# PM_RT register map
Vendor: Texas Instruments
Peripheral module from a debugger description file (folder omap34xx).
Registers are 64-bit, access per field, reset 0x0 unless marked. A register's access mark holds for its fields unless they carry their own. Offsets are as the file gives them; lines under a group give offsets from that group; [hi:lo] are bit positions; {n}, {i} and the like mark numbered series; 'fields as' and 'values as' point back to an identical list; <NAME> marks a mode.

## PM_RT
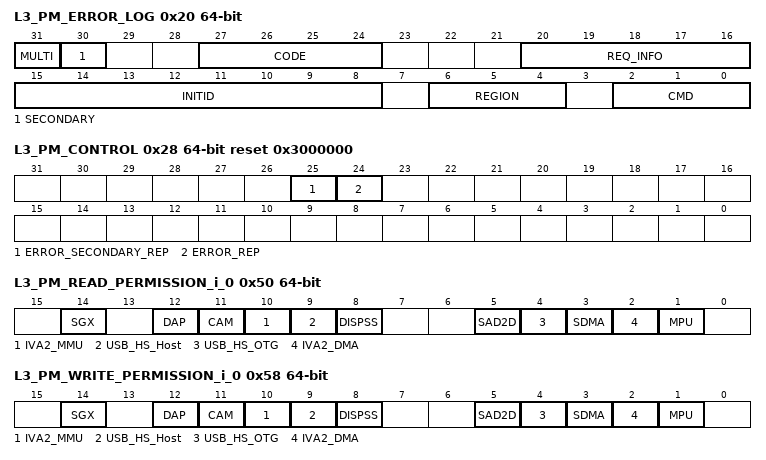
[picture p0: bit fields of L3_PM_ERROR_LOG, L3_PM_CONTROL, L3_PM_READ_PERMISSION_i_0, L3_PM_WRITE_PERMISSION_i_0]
0x20 L3_PM_ERROR_LOG access not given — This register logs errors detected by the protection mechanism.
  [31] MULTI — Multiple errors (access RW1toClr)
    0=Multiple errors not seen; 1=Multiple errors seen
  [30] SECONDARY — Secondary error present (access RW1toClr)
  [27:24] CODE — Error Code see (access RW1toClr)
  [20:16] REQ_INFO ro — MReqInfo bits of command selected for protection checking see
  [15:8] INITID ro — Initiator ID from which the command was launched see
  [6:4] REGION ro — Protection region number that command mapped to
  [2:0] CMD ro — Command that caused the error see
0x28 L3_PM_CONTROL reset 0x3000000 — This register controls protection mechanism functions such as error reporting.
  [25] ERROR_SECONDARY_REP rw — Out of band error reporting
    0=Out of band error reporting suppress; 1=Out of band error report
  [24] ERROR_REP rw — Out of band error reporting
    values as ERROR_SECONDARY_REP
0x30 L3_PM_ERROR_CLEAR_SINGLE ro — Read to clear single errors from error log
  [0] CLEAR — Clear single error from log
0x38 L3_PM_ERROR_CLEAR_MULTI ro — Read to clear multiple errors from error log
  [0] CLEAR — Clear multiple error from log
0x48 L3_PM_REQ_INFO_PERMISSION_i_0 (reset mask 0xFFFFFFFFFFFF0000) — It configures a protection region's permissions using the MReqInfo bits selected for the PM by the structural configuration.
  [15:0] REQ_INFO rw — Request info permission bits for region i, see for bitfield description.
0x50 L3_PM_READ_PERMISSION_i_0 (reset mask 0xFFFFFFFFFFFFA0C1) — It configures protection region permissions for read incoming commands.
  [14] SGX rw — Read permission for the SGX
  [12] DAP rw — Read permission for the DAP
  [11] CAM rw — Read permission for the CAMERA SS
  [10] IVA2_MMU rw — Read permission for the IVA2 MMU
  [9] USB_HS_Host rw — Read permission for theUSB_HS_Host
  [8] DISPSS rw — Write permission for the DISPLAY SS
  [5] SAD2D rw — Read permission for theSAD2D
  [4] USB_HS_OTG rw — Read permission for theUSB_HS_OTG
  [3] SDMA rw — Read permission for the system DMA
  [2] IVA2_DMA rw — Read permission for the IVA2
  [1] MPU rw — Read permission for the MPU
0x58 L3_PM_WRITE_PERMISSION_i_0 (reset mask 0xFFFFFFFFFFFFA0C1) — It configures protection region permissions for write incoming commands.
  [14] SGX rw — Write permission for the SGX
  [12] DAP rw — Write permission for the DAP
  [11] CAM rw — Write permission for the CAMERA SS
  [10] IVA2_MMU rw — Write permission for the IVA2 MMU
  [9] USB_HS_Host rw — Write permission for theUSB_HS_Host
  [8] DISPSS rw — Write permission for the DISPLAY SS
  [5] SAD2D rw — Write permission for theSAD2D
  [4] USB_HS_OTG rw — Write permission for theUSB_HS_OTG
  [3] SDMA rw — Write permission for the system DMA
  [2] IVA2_DMA rw — Write permission for the IVA2
  [1] MPU rw — Write permission for the MPU
0x68 L3_PM_REQ_INFO_PERMISSION_i_1 (reset mask 0xFFFFFFFFFFFF0000) — It configures a protection region's permissions using the MReqInfo bits selected for the PM by the structural configuration.
  fields as L3_PM_REQ_INFO_PERMISSION_i_0
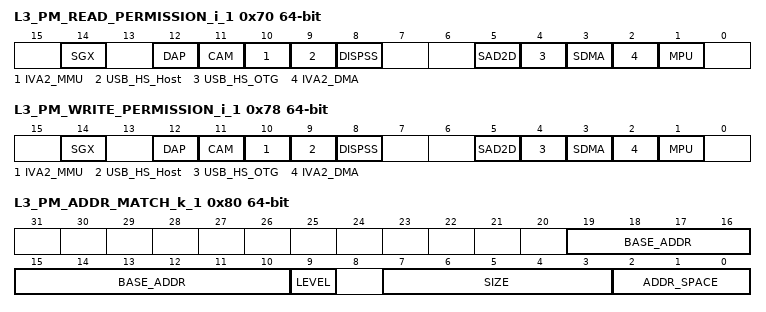
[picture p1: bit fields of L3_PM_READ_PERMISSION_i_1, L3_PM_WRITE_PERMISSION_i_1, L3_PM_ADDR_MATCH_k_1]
0x70 L3_PM_READ_PERMISSION_i_1 (reset mask 0xFFFFFFFFFFFFA0C1) — It configures protection region permissions for read incoming commands.
  fields as L3_PM_READ_PERMISSION_i_0
0x78 L3_PM_WRITE_PERMISSION_i_1 (reset mask 0xFFFFFFFFFFFFA0C1) — It configures protection region permissions for write incoming commands.
  fields as L3_PM_WRITE_PERMISSION_i_0
0x80 L3_PM_ADDR_MATCH_k_1 ro (reset mask 0xFFFFFFFFFFF00100)
  [19:10] BASE_ADDR — Protection region base address
  [9] LEVEL — Protection region level.
  [7:3] SIZE — Protection region size
  [2:0] ADDR_SPACE — Protection region address space
